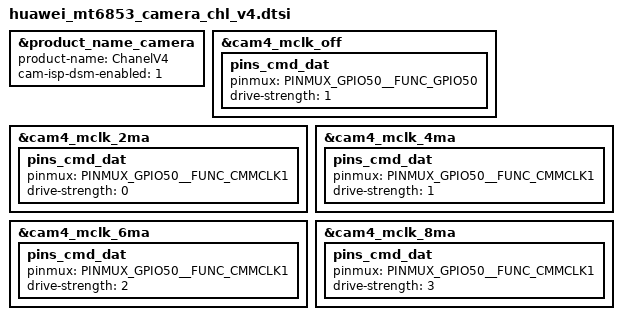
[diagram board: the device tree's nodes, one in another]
/*
 * Copyright (c) 2019 MediaTek Inc.
 *
 * This program is free software; you can redistribute it and/or modify
 * it under the terms of the GNU General Public License version 2 as
 * published by the Free Software Foundation.
 *
 * This program is distributed in the hope that it will be useful,
 * but WITHOUT ANY WARRANTY; without even the implied warranty of
 * MERCHANTABILITY or FITNESS FOR A PARTICULAR PURPOSE.  See the
 * GNU General Public License for more details.
 */
#include "huawei_mt6853_camera_chl.dtsi"
&product_name_camera {
	product-name = "ChanelV4";
	cam-isp-dsm-enabled = <1>;
};

/* CAMERA GPIO standardization */

&cam4_mclk_off {
	pins_cmd_dat {
		pinmux = <PINMUX_GPIO50__FUNC_GPIO50>;
		drive-strength = <1>;
	};
};

&cam4_mclk_2ma {
	pins_cmd_dat {
		pinmux = <PINMUX_GPIO50__FUNC_CMMCLK1>;
		drive-strength = <0>;
	};
};

&cam4_mclk_4ma {
	pins_cmd_dat {
		pinmux = <PINMUX_GPIO50__FUNC_CMMCLK1>;
		drive-strength = <1>;
	};
};

&cam4_mclk_6ma {
	pins_cmd_dat {
		pinmux = <PINMUX_GPIO50__FUNC_CMMCLK1>;
		drive-strength = <2>;
	};
};

&cam4_mclk_8ma {
	pins_cmd_dat {
		pinmux = <PINMUX_GPIO50__FUNC_CMMCLK1>;
		drive-strength = <3>;
	};
};
/* Main4(macro) Cam: cam4 GPIOs end */

